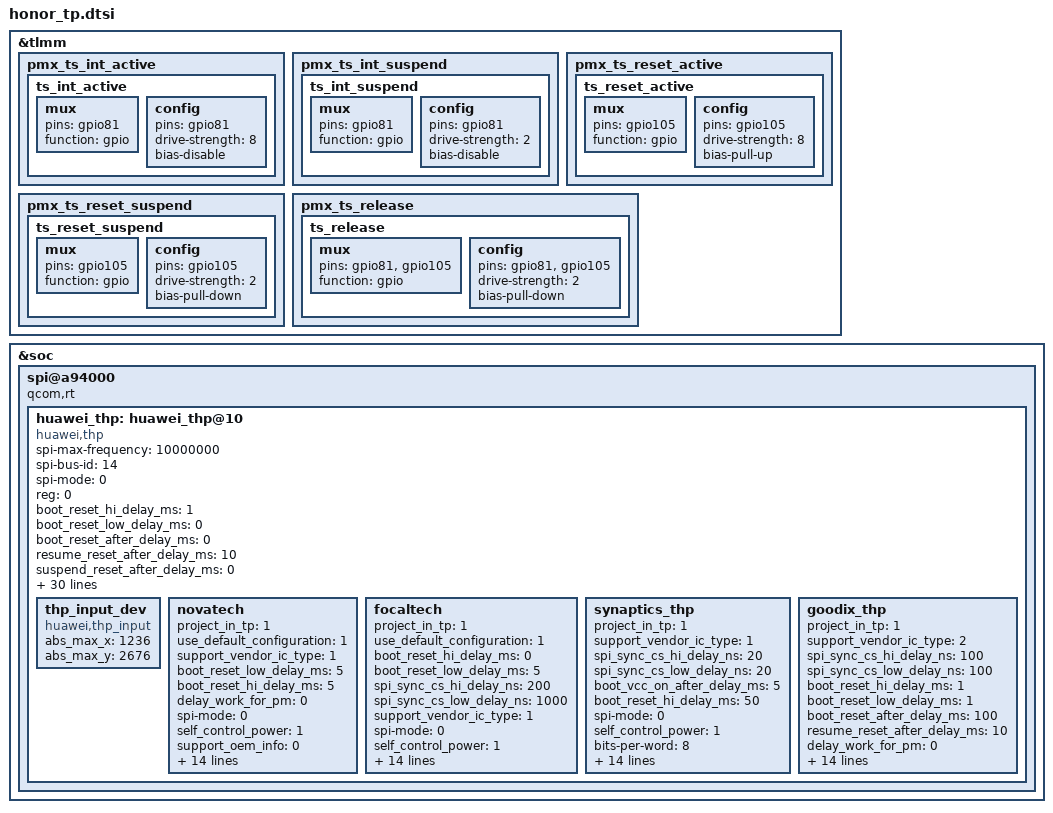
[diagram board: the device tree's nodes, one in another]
/* touch panel config */
&tlmm {
	pmx_ts_int_active {
		ts_int_active: ts_int_active {
			mux {
				pins = "gpio81";
				function = "gpio";
			};

			config {
				pins = "gpio81";
				drive-strength = <8>;
				bias-disable;
			};
		};
	};

	pmx_ts_int_suspend {
		ts_int_suspend: ts_int_suspend {
			mux {
				pins = "gpio81";
				function = "gpio";
			};

			config {
				pins = "gpio81";
				drive-strength = <2>;
				bias-disable;
			};
		};
	};

	pmx_ts_reset_active {
		ts_reset_active: ts_reset_active {
			mux {
				pins = "gpio105";
				function = "gpio";
			};

			config {
				pins = "gpio105";
				drive-strength = <8>;
				bias-pull-up;
			};
		};
	};

	pmx_ts_reset_suspend {
		ts_reset_suspend: ts_reset_suspend {
			mux {
				pins = "gpio105";
				function = "gpio";
			};

			config {
				pins = "gpio105";
				drive-strength = <2>;
				bias-pull-down;
			};
		};
	};

	pmx_ts_release {
		ts_release: ts_release {
			mux {
				pins = "gpio81", "gpio105";
				function = "gpio";
			};

			config {
				pins = "gpio81", "gpio105";
				drive-strength = <2>;
				bias-pull-down;
			};
		};
	};
};

&soc {
	spi@a94000 {
		status = "ok";
		qcom,rt;
		#address-cells = <1>;
		#size-cells = <0>;
		huawei_thp: huawei_thp@10 {
			compatible = "huawei,thp";
			/* SPI Config */
			spi-max-frequency = <10000000>;
			spi-bus-id = <14>;
			spi-mode = <0>;
			reg = <0>;

			/* Timing */
			boot_reset_hi_delay_ms = <1>;
			boot_reset_low_delay_ms = <0>;
			boot_reset_after_delay_ms = <0>;
			resume_reset_after_delay_ms = <10>;
			suspend_reset_after_delay_ms = <0>;
			spi_sync_cs_hi_delay_ns = <200>;
			spi_sync_cs_low_delay_ns = <10>;
			use_mdelay = <1>;

			/* GPIO Config */
			irq_flag = <0x00004002>;
			interrupt-parent = <&tlmm>;
			interrupts = <81 0>;
			rst_gpio = <&tlmm 105 0x00>;
			irq_gpio = <&tlmm 81 0x00>;
			cs_gpio = <&tlmm 55 0x00>;

			thp-vcc-type = <1>; /* 0-unsued 1-ldo 2-gpio */
			thp-vcc-supply = <&L3C>;
			thp-vcc-value = <3100000>;

			thp-iovdd-type = <1>;
			thp-iovdd-supply = <&L2C>;
			thp-iovdd-value = <1800000>;

			/* Feature Config */
			pt_station_test = <1>;
			proximity_support = <0>;
			hide_product_info_en = <1>;
			support_vendor_ic_type = <1>;
			supported_charger = <1>;
			fast_booting_solution = <1>;
			support_gesture_mode = <1>;
			need_enable_irq_wake = <1>;
			need_notify_to_roi_algo = <1>;
			support_b_protocol = <0>;
			support_irq_storm_protect = <1>;
			support_pinctrl = <1>;
			pinctrl_init_enable = <1>;
			pinctrl-names = "default", "idle";
					pinctrl-0 = <&ts_int_active>;
					pinctrl-1 = <&ts_int_suspend>;

			thp_input_dev {
				compatible = "huawei,thp_input";
				abs_max_x = <1236>;
				abs_max_y = <2676>;
			};
			novatech {
				project_in_tp = <1>;
				use_default_configuration = <1>;
				support_vendor_ic_type = <1>;
				boot_reset_low_delay_ms = <5>;
				boot_reset_hi_delay_ms = <5>;
				delay_work_for_pm = <0>;
				spi-mode = <0>;
				self_control_power = <1>;
				support_oem_info = <0>;
				support_gesture_mode = <0>;
				use_ap_gesture = <1>;
				support_fingerprint_switch = <1>;
				aod_display_support = <1>;
				use_aod_power_ctrl_notify = <1>;
				need_huge_memory_in_spi = <1>;
				edit_product_in_project_id = <0>;
				spi_sync_cs_hi_delay_ns = <200>;
				spi_sync_cs_low_delay_ns = <1000>;
				change_spi_driving_force = <1>;
				need_enable_irq_wake = <1>;
				suspend_delayms_early_to_before = <150>;
				suspend_delayms_before_to_later = <15>;
				resume_delayms_early_to_later = <150>;
			};
			focaltech {
				project_in_tp = <1>;
				use_default_configuration = <1>;
				boot_reset_hi_delay_ms = <0>;
				boot_reset_low_delay_ms = <5>;
				spi_sync_cs_hi_delay_ns = <200>;
				spi_sync_cs_low_delay_ns = <1000>;
				support_vendor_ic_type = <1>;
				spi-mode = <0>;
				self_control_power = <1>;
				support_oem_info = <0>;
				support_gesture_mode = <0>;
				change_spi_driving_force = <1>;
				use_ap_gesture = <1>;
				support_fingerprint_switch = <1>;
				aod_display_support = <1>;
				use_aod_power_ctrl_notify = <1>;
				need_huge_memory_in_spi = <1>;
				edit_product_in_project_id = <0>;
				reset_status_in_suspend_mode = <1>;
				need_enable_irq_wake = <1>;
				suspend_delayms_early_to_before = <150>;
				suspend_delayms_before_to_later = <15>;
				resume_delayms_early_to_later = <150>;
			};
			synaptics_thp {
				project_in_tp = <1>;
				support_vendor_ic_type = <1>;
				spi_sync_cs_hi_delay_ns = <20>;
				spi_sync_cs_low_delay_ns = <20>;
				boot_vcc_on_after_delay_ms = <5>;
				boot_reset_hi_delay_ms = <50>;
				spi-mode = <0>;
				self_control_power = <1>;
				bits-per-word = <8>;
				support_gesture_mode = <1>;
				need_enable_irq_wake = <1>;
				use_ap_gesture = <1>;
				support_fingerprint_switch = <1>;
				aod_display_support = <1>;
				need_huge_memory_in_spi = <1>;
				edit_product_in_project_id = <0>;
				use_aod_power_ctrl_notify = <1>;
				suspend_delayms_early_to_before = <150>;
				suspend_delayms_before_to_later = <15>;
				resume_delayms_early_to_later = <60>;
				/* IRQF_TRIGGER_LOW 0x00000008 */
				irq_flag = <0x00000008>;
				support_get_frame_read_once = <1>;
				send_one_cmd_for_ap = <1>;
			};
			goodix_thp {
				project_in_tp = <1>;
				support_vendor_ic_type = <2>;
				spi_sync_cs_hi_delay_ns = <100>;
				spi_sync_cs_low_delay_ns = <100>;
				boot_reset_hi_delay_ms = <1>;
				boot_reset_low_delay_ms = <1>;
				boot_reset_after_delay_ms = <100>;
				resume_reset_after_delay_ms = <10>;
				delay_work_for_pm = <0>;
				support_gesture_mode = <1>;
				need_enable_irq_wake = <1>;
				use_ap_gesture = <1>;
				support_fingerprint_switch = <1>;
				aod_display_support = <1>;
				support_oem_info = <0>;
				need_resume_reset = <0>;
				gesture_mode_double_tap = <1>;
				edit_product_in_project_id = <0>;
				use_aod_power_ctrl_notify = <1>;
				suspend_delayms_early_to_before = <150>;
				suspend_delayms_before_to_later = <15>;
				resume_delayms_early_to_later = <150>;
				support_lowpower_no_irq = <1>;
			};
		};
	};
};
